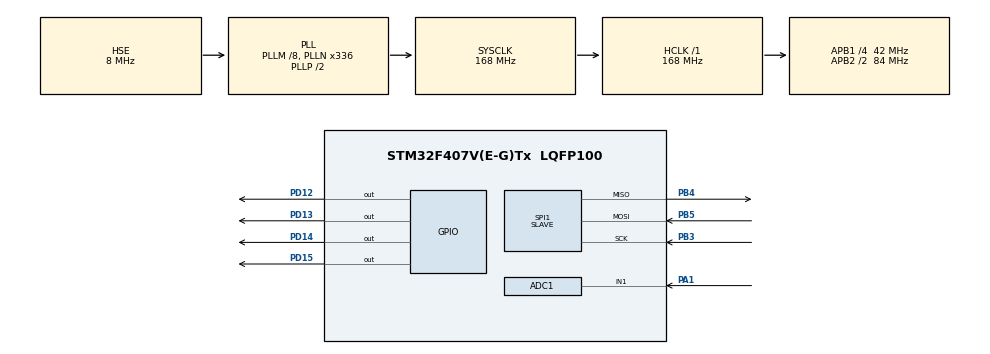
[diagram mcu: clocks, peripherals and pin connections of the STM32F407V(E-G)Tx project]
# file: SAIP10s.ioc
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ADC1.Channel-0\#ChannelRegularConversion=ADC_CHANNEL_1
ADC1.ContinuousConvMode=ENABLE
ADC1.EOCSelection=ADC_EOC_SEQ_CONV
ADC1.NbrOfConversionFlag=1
ADC1.Rank-0\#ChannelRegularConversion=1
ADC1.SamplingTime-0\#ChannelRegularConversion=ADC_SAMPLETIME_3CYCLES
ADC1.master=1
Mcu.Family=STM32F4
Mcu.Name=STM32F407V(E-G)Tx
Mcu.Package=LQFP100
NVIC.PriorityGroup=NVIC_PRIORITYGROUP_0
NVIC.SPI1_IRQn=true\:0\:5\:false\:false\:true\:true\:true
PA1.Signal=ADCx_IN1
PB3.Mode=Full_Duplex_Slave
PB3.Signal=SPI1_SCK
PB4.Mode=Full_Duplex_Slave
PB4.Signal=SPI1_MISO
PB5.Mode=Full_Duplex_Slave
PB5.Signal=SPI1_MOSI
PD12.Signal=GPIO_Output
PD13.Signal=GPIO_Output
PD14.Signal=GPIO_Output
PD15.Signal=GPIO_Output
PH0-OSC_IN.Mode=HSE-External-Oscillator
PH0-OSC_IN.Signal=RCC_OSC_IN
PH1-OSC_OUT.Mode=HSE-External-Oscillator
PH1-OSC_OUT.Signal=RCC_OSC_OUT
ProjectManager.HeapSize=0x200
ProjectManager.StackSize=0x400
ProjectManager.TargetToolchain=EWARM V8.32
RCC.48MHZClocksFreq_Value=48000000
RCC.AHBFreq_Value=168000000
RCC.APB1CLKDivider=RCC_HCLK_DIV4
RCC.APB1Freq_Value=42000000
RCC.APB1TimFreq_Value=84000000
RCC.APB2CLKDivider=RCC_HCLK_DIV2
RCC.APB2Freq_Value=84000000
RCC.APB2TimFreq_Value=168000000
RCC.CortexFreq_Value=168000000
RCC.HCLKFreq_Value=168000000
RCC.HSE_VALUE=8000000
RCC.HSI_VALUE=16000000
RCC.LSE_VALUE=32768
RCC.PLLM=8
RCC.PLLN=336
RCC.PLLQ=7
RCC.PLLSourceVirtual=RCC_PLLSOURCE_HSE
RCC.SYSCLKFreq_VALUE=168000000
RCC.SYSCLKSource=RCC_SYSCLKSOURCE_PLLCLK
RCC.VCOOutputFreq_Value=336000000
SH.ADCx_IN1.0=ADC1_IN1,IN1
SPI1.Direction=SPI_DIRECTION_2LINES
SPI1.Mode=SPI_MODE_SLAVE
SPI1.VirtualType=VM_SLAVE
board=STM32F407G-DISC1

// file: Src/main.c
/* USER CODE BEGIN Header */
/**
  ******************************************************************************
  * @file           : main.c
  * @brief          : Main program body
  ******************************************************************************
  * @attention
  *
  * <h2><center>&copy; Copyright (c) 2020 STMicroelectronics.
  * All rights reserved.</center></h2>
  *
  * This software component is licensed by ST under BSD 3-Clause license,
  * the "License"; You may not use this file except in compliance with the
  * License. You may obtain a copy of the License at:
  *                        opensource.org/licenses/BSD-3-Clause
  *
  ******************************************************************************
  */
/* USER CODE END Header */

#include "main.h"

/* USER CODE BEGIN Includes */
#include "stdio.h"
/* USER CODE END Includes */

ADC_HandleTypeDef hadc1;

SPI_HandleTypeDef hspi1;

/* USER CODE BEGIN PV */
uint8_t RxData[5];
char TxData[5];
uint16_t t;
/* USER CODE END PV */

void SystemClock_Config(void);
static void MX_GPIO_Init(void);
static void MX_SPI1_Init(void);
static void MX_ADC1_Init(void);

int main(void)
{

  /* MCU Configuration--------------------------------------------------------*/

  /* Reset of all peripherals, Initializes the Flash interface and the Systick. */
  HAL_Init();

  /* Configure the system clock */
  SystemClock_Config();

  /* Initialize all configured peripherals */
  MX_GPIO_Init();
  MX_SPI1_Init();
  MX_ADC1_Init();
  /* USER CODE BEGIN 2 */
HAL_ADC_Start(&hadc1);
HAL_SPI_TransmitReceive_IT(&hspi1, (uint8_t *)TxData,(uint8_t *)RxData,5);
  /* USER CODE END 2 */

  /* Infinite loop */
  /* USER CODE BEGIN WHILE */
  while (1)
  {
   // HAL_Delay(200);
    /* USER CODE END WHILE */

  }
}

void SystemClock_Config(void)
{
  RCC_OscInitTypeDef RCC_OscInitStruct = {0};
  RCC_ClkInitTypeDef RCC_ClkInitStruct = {0};

  /** Configure the main internal regulator output voltage
  */
  __HAL_RCC_PWR_CLK_ENABLE();
  __HAL_PWR_VOLTAGESCALING_CONFIG(PWR_REGULATOR_VOLTAGE_SCALE1);
  /** Initializes the CPU, AHB and APB busses clocks
  */
  RCC_OscInitStruct.OscillatorType = RCC_OSCILLATORTYPE_HSE;
  RCC_OscInitStruct.HSEState = RCC_HSE_ON;
  RCC_OscInitStruct.PLL.PLLState = RCC_PLL_ON;
  RCC_OscInitStruct.PLL.PLLSource = RCC_PLLSOURCE_HSE;
  RCC_OscInitStruct.PLL.PLLM = 8;
  RCC_OscInitStruct.PLL.PLLN = 336;
  RCC_OscInitStruct.PLL.PLLP = RCC_PLLP_DIV2;
  RCC_OscInitStruct.PLL.PLLQ = 7;
  if (HAL_RCC_OscConfig(&RCC_OscInitStruct) != HAL_OK)
  {
    Error_Handler();
  }
  /** Initializes the CPU, AHB and APB busses clocks
  */
  RCC_ClkInitStruct.ClockType = RCC_CLOCKTYPE_HCLK|RCC_CLOCKTYPE_SYSCLK
                              |RCC_CLOCKTYPE_PCLK1|RCC_CLOCKTYPE_PCLK2;
  RCC_ClkInitStruct.SYSCLKSource = RCC_SYSCLKSOURCE_PLLCLK;
  RCC_ClkInitStruct.AHBCLKDivider = RCC_SYSCLK_DIV1;
  RCC_ClkInitStruct.APB1CLKDivider = RCC_HCLK_DIV4;
  RCC_ClkInitStruct.APB2CLKDivider = RCC_HCLK_DIV2;

  if (HAL_RCC_ClockConfig(&RCC_ClkInitStruct, FLASH_LATENCY_5) != HAL_OK)
  {
    Error_Handler();
  }
}

static void MX_ADC1_Init(void)
{

  ADC_ChannelConfTypeDef sConfig = {0};

  /** Configure the global features of the ADC (Clock, Resolution, Data Alignment and number of conversion)
  */
  hadc1.Instance = ADC1;
  hadc1.Init.ClockPrescaler = ADC_CLOCK_SYNC_PCLK_DIV4;
  hadc1.Init.Resolution = ADC_RESOLUTION_12B;
  hadc1.Init.ScanConvMode = DISABLE;
  hadc1.Init.ContinuousConvMode = ENABLE;
  hadc1.Init.DiscontinuousConvMode = DISABLE;
  hadc1.Init.ExternalTrigConvEdge = ADC_EXTERNALTRIGCONVEDGE_NONE;
  hadc1.Init.ExternalTrigConv = ADC_SOFTWARE_START;
  hadc1.Init.DataAlign = ADC_DATAALIGN_RIGHT;
  hadc1.Init.NbrOfConversion = 1;
  hadc1.Init.DMAContinuousRequests = DISABLE;
  hadc1.Init.EOCSelection = ADC_EOC_SEQ_CONV;
  if (HAL_ADC_Init(&hadc1) != HAL_OK)
  {
    Error_Handler();
  }
  /** Configure for the selected ADC regular channel its corresponding rank in the sequencer and its sample time.
  */
  sConfig.Channel = ADC_CHANNEL_1;
  sConfig.Rank = 1;
  sConfig.SamplingTime = ADC_SAMPLETIME_3CYCLES;
  if (HAL_ADC_ConfigChannel(&hadc1, &sConfig) != HAL_OK)
  {
    Error_Handler();
  }

}

static void MX_SPI1_Init(void)
{

  /* SPI1 parameter configuration*/
  hspi1.Instance = SPI1;
  hspi1.Init.Mode = SPI_MODE_SLAVE;
  hspi1.Init.Direction = SPI_DIRECTION_2LINES;
  hspi1.Init.DataSize = SPI_DATASIZE_8BIT;
  hspi1.Init.CLKPolarity = SPI_POLARITY_LOW;
  hspi1.Init.CLKPhase = SPI_PHASE_1EDGE;
  hspi1.Init.NSS = SPI_NSS_SOFT;
  hspi1.Init.FirstBit = SPI_FIRSTBIT_MSB;
  hspi1.Init.TIMode = SPI_TIMODE_DISABLE;
  hspi1.Init.CRCCalculation = SPI_CRCCALCULATION_DISABLE;
  hspi1.Init.CRCPolynomial = 10;
  if (HAL_SPI_Init(&hspi1) != HAL_OK)
  {
    Error_Handler();
  }

}

static void MX_GPIO_Init(void)
{
  GPIO_InitTypeDef GPIO_InitStruct = {0};

  /* GPIO Ports Clock Enable */
  __HAL_RCC_GPIOH_CLK_ENABLE();
  __HAL_RCC_GPIOA_CLK_ENABLE();
  __HAL_RCC_GPIOD_CLK_ENABLE();
  __HAL_RCC_GPIOB_CLK_ENABLE();

  /*Configure GPIO pin Output Level */
  HAL_GPIO_WritePin(GPIOD, GPIO_PIN_12|GPIO_PIN_13|GPIO_PIN_14|GPIO_PIN_15, GPIO_PIN_RESET);

  /*Configure GPIO pins : PD12 PD13 PD14 PD15 */
  GPIO_InitStruct.Pin = GPIO_PIN_12|GPIO_PIN_13|GPIO_PIN_14|GPIO_PIN_15;
  GPIO_InitStruct.Mode = GPIO_MODE_OUTPUT_PP;
  GPIO_InitStruct.Pull = GPIO_NOPULL;
  GPIO_InitStruct.Speed = GPIO_SPEED_FREQ_LOW;
  HAL_GPIO_Init(GPIOD, &GPIO_InitStruct);

}

/* USER CODE BEGIN 4 */
void HAL_SPI_TxRxCpltCallback(SPI_HandleTypeDef *hspi)
{
  if (RxData[4]=='1')
    {
    GPIOD->ODR^=1<<15;
    t=HAL_ADC_GetValue(&hadc1);
    sprintf(TxData,"%04d\n",t);
    HAL_SPI_TransmitReceive_IT(&hspi1, (uint8_t *)TxData,(uint8_t *)RxData,5);
    }
}
/* USER CODE END 4 */

void Error_Handler(void)
{
}

/************************ (C) COPYRIGHT STMicroelectronics *****END OF FILE****/
